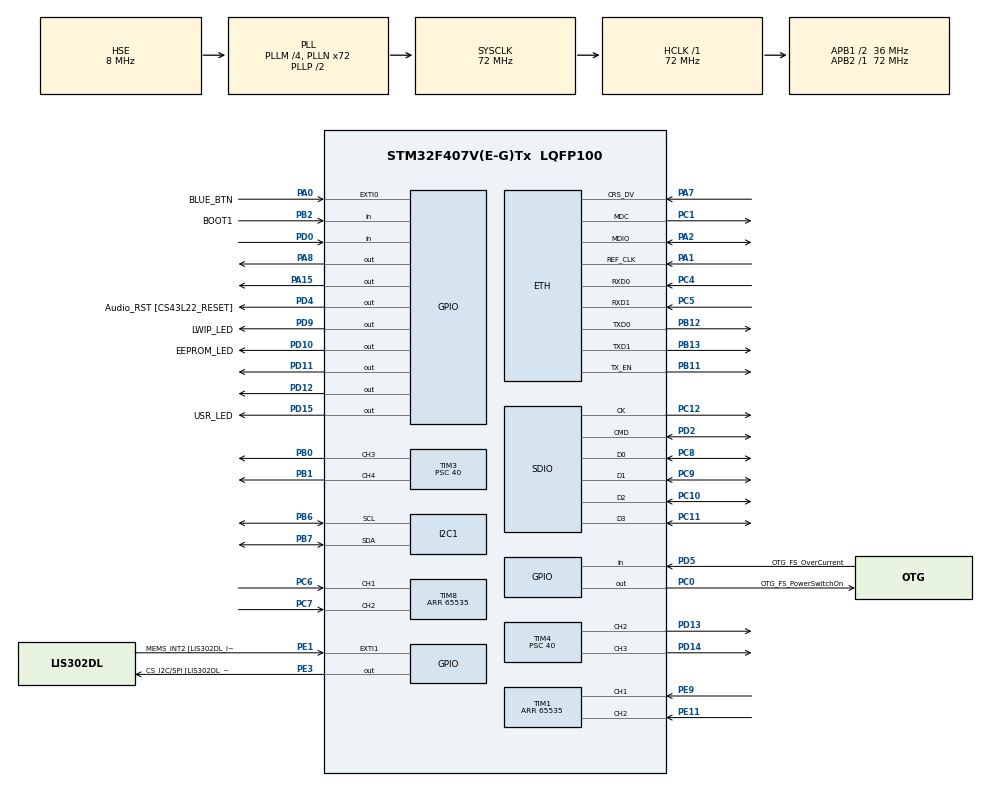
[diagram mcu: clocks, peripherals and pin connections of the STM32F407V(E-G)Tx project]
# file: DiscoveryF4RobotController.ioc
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ETH.MediaInterface=ETH_MEDIA_INTERFACE_RMII
ETH.PhyAddress=0
FATFS.BSP.number=1
FATFS0.BSP.STBoard=false
FATFS0.BSP.api=Unknown
FATFS0.BSP.i2caddr=0
FATFS0.BSP.instance=PD0
FATFS0.BSP.ip=GPIO
FATFS0.BSP.mode=Input
FATFS0.BSP.name=Detect_SDIO
FATFS0.BSP.solution=PD0
FREERTOS.HEAP_NUMBER=5
FREERTOS.Tasks01=defaultTask,0,128,StartDefaultTask,Default,NULL
LWIP.ARP_MAXAGE=6000
LWIP.CHECKSUM_CHECK_IP=1
LWIP.CHECKSUM_GEN_IP=1
LWIP.GATEWAY_ADDRESS=198.168.002.001
LWIP.IP_ADDRESS=192.168.002.114
LWIP.LWIP_ARP=1
LWIP.LWIP_DHCP=0
LWIP.MEMP_NUM_TCP_SEG=24
LWIP.MEM_SIZE=2048
LWIP.NETMASK_ADDRESS=255.255.255.000
LWIP.TCP_MSS=460
LWIP.TCP_SND_BUF=1840
LWIP.TCP_WND=2048
LWIP.Version=v2.0.3_Cube
Mcu.Family=STM32F4
Mcu.Name=STM32F407V(E-G)Tx
Mcu.Package=LQFP100
NVIC.ETH_IRQn=true\:5\:0\:false\:false\:true\:true\:false\:true
NVIC.EXTI0_IRQn=true\:5\:0\:false\:false\:true\:true\:true\:true
NVIC.PriorityGroup=NVIC_PRIORITYGROUP_4
NVIC.TIM2_IRQn=true\:0\:0\:false\:false\:true\:false\:false\:true
NVIC.TimeBase=TIM2_IRQn
NVIC.TimeBaseIP=TIM2
PA0-WKUP.GPIO_Label=BLUE_BTN
PA0-WKUP.GPIO_PuPd=GPIO_PULLDOWN
PA0-WKUP.Signal=GPXTI0
PA1.Mode=RMII
PA1.Signal=ETH_REF_CLK
PA13.GPIO_Label=SWDIO
PA13.Mode=Serial_Wire
PA13.Signal=SYS_JTMS-SWDIO
PA14.GPIO_Label=SWCLK
PA14.Mode=Serial_Wire
PA14.Signal=SYS_JTCK-SWCLK
PA15.Signal=GPIO_Output
PA2.Mode=RMII
PA2.Signal=ETH_MDIO
PA7.Mode=RMII
PA7.Signal=ETH_CRS_DV
PA8.Signal=GPIO_Output
PB0.Signal=S_TIM3_CH3
PB1.Signal=S_TIM3_CH4
PB11.Mode=RMII
PB11.Signal=ETH_TX_EN
PB12.Mode=RMII
PB12.Signal=ETH_TXD0
PB13.Mode=RMII
PB13.Signal=ETH_TXD1
PB2.GPIO_Label=BOOT1
PB2.GPIO_Mode=GPIO_MODE_INPUT
PB2.GPIO_PuPd=GPIO_NOPULL
PB2.Signal=GPIO_Input
PB6.Mode=I2C
PB6.Signal=I2C1_SCL
PB7.Mode=I2C
PB7.Signal=I2C1_SDA
PC0.GPIO_Label=OTG_FS_PowerSwitchOn
PC0.GPIO_PuPd=GPIO_NOPULL
PC0.GPIO_Speed=GPIO_SPEED_FREQ_LOW
PC0.PinState=GPIO_PIN_SET
PC0.Signal=GPIO_Output
PC1.Mode=RMII
PC1.Signal=ETH_MDC
PC10.Mode=SD_4_bits_Wide_bus
PC10.Signal=SDIO_D2
PC11.Mode=SD_4_bits_Wide_bus
PC11.Signal=SDIO_D3
PC12.Mode=SD_4_bits_Wide_bus
PC12.Signal=SDIO_CK
PC4.Mode=RMII
PC4.Signal=ETH_RXD0
PC5.Mode=RMII
PC5.Signal=ETH_RXD1
PC6.Signal=S_TIM8_CH1
PC7.Signal=S_TIM8_CH2
PC8.Mode=SD_4_bits_Wide_bus
PC8.Signal=SDIO_D0
PC9.Mode=SD_4_bits_Wide_bus
PC9.Signal=SDIO_D1
PD0.Signal=GPIO_Input
PD10.GPIO_Label=EEPROM_LED
PD10.Signal=GPIO_Output
PD11.Signal=GPIO_Output
PD12.Signal=GPIO_Output
PD13.Signal=S_TIM4_CH2
PD14.Signal=S_TIM4_CH3
PD15.GPIO_Label=USR_LED
PD15.Signal=GPIO_Output
PD2.Mode=SD_4_bits_Wide_bus
PD2.Signal=SDIO_CMD
PD4.GPIO_Label=Audio_RST [CS43L22_RESET]
PD4.GPIO_PuPd=GPIO_NOPULL
PD4.GPIO_Speed=GPIO_SPEED_FREQ_LOW
PD4.Signal=GPIO_Output
PD5.GPIO_Label=OTG_FS_OverCurrent
PD5.GPIO_Mode=GPIO_MODE_INPUT
PD5.GPIO_PuPd=GPIO_NOPULL
PD5.Signal=GPIO_Input
PD9.GPIO_Label=LWIP_LED
PD9.Signal=GPIO_Output
PE1.GPIO_Label=MEMS_INT2 [LIS302DL_INT2]
PE1.GPIO_ModeDefaultEXTI=GPIO_MODE_EVT_RISING
PE1.GPIO_PuPd=GPIO_NOPULL
PE1.Signal=GPXTI1
PE11.Signal=S_TIM1_CH2
PE3.GPIO_Label=CS_I2C/SPI [LIS302DL_CS_I2C/SPI]
PE3.GPIO_PuPd=GPIO_NOPULL
PE3.GPIO_Speed=GPIO_SPEED_FREQ_LOW
PE3.Signal=GPIO_Output
PE9.Signal=S_TIM1_CH1
PH0-OSC_IN.GPIO_Label=PH0-OSC_IN
PH0-OSC_IN.Mode=HSE-External-Clock-Source
PH0-OSC_IN.Signal=RCC_OSC_IN
PH1-OSC_OUT.GPIO_Label=PH1-OSC_OUT
PH1-OSC_OUT.Mode=HSE-External-Clock-Source
PH1-OSC_OUT.Signal=RCC_OSC_OUT
ProjectManager.HeapSize=0x200
ProjectManager.StackSize=0x400
ProjectManager.TargetToolchain=STM32CubeIDE
RCC.48MHZClocksFreq_Value=20571428.57142857
RCC.AHBFreq_Value=72000000
RCC.APB1CLKDivider=RCC_HCLK_DIV2
RCC.APB1Freq_Value=36000000
RCC.APB1TimFreq_Value=72000000
RCC.APB2Freq_Value=72000000
RCC.APB2TimFreq_Value=72000000
RCC.CortexFreq_Value=72000000
RCC.HCLKFreq_Value=72000000
RCC.HSE_VALUE=8000000
RCC.HSI_VALUE=16000000
RCC.LSE_VALUE=32768
RCC.PLLM=4
RCC.PLLN=72
RCC.PLLQ=7
RCC.PLLSourceVirtual=RCC_PLLSOURCE_HSE
RCC.SYSCLKFreq_VALUE=72000000
RCC.SYSCLKSource=RCC_SYSCLKSOURCE_PLLCLK
RCC.VCOOutputFreq_Value=144000000
SH.S_TIM1_CH1.0=TIM1_CH1,Encoder_Interface
SH.S_TIM1_CH2.0=TIM1_CH2,Encoder_Interface
SH.S_TIM3_CH3.0=TIM3_CH3,PWM Generation3 CH3
SH.S_TIM3_CH4.0=TIM3_CH4,PWM Generation4 CH4
SH.S_TIM4_CH2.0=TIM4_CH2,PWM Generation2 CH2
SH.S_TIM4_CH3.0=TIM4_CH3,PWM Generation3 CH3
SH.S_TIM8_CH1.0=TIM8_CH1,Encoder_Interface
SH.S_TIM8_CH2.0=TIM8_CH2,Encoder_Interface
TIM1.EncoderMode=TIM_ENCODERMODE_TI12
TIM1.IC1Filter=0
TIM1.IC1Prescaler=TIM_ICPSC_DIV1
TIM1.IC2Filter=0
TIM1.IC2Polarity=TIM_ICPOLARITY_FALLING
TIM1.IC2Prescaler=TIM_ICPSC_DIV1
TIM1.Period=65535
TIM3.Channel-PWM\ Generation3\ CH3=TIM_CHANNEL_3
TIM3.Channel-PWM\ Generation4\ CH4=TIM_CHANNEL_4
TIM3.Period=256
TIM3.Prescaler=40
TIM4.Channel-PWM\ Generation2\ CH2=TIM_CHANNEL_2
TIM4.Channel-PWM\ Generation3\ CH3=TIM_CHANNEL_3
TIM4.Period=256
TIM4.Prescaler=40
TIM8.EncoderMode=TIM_ENCODERMODE_TI12
TIM8.IC1Filter=0
TIM8.IC1Prescaler=TIM_ICPSC_DIV1
TIM8.IC2Filter=15
TIM8.IC2Polarity=TIM_ICPOLARITY_FALLING
TIM8.IC2Prescaler=TIM_ICPSC_DIV1
TIM8.Period=65535
VP_FATFS_VS_SDIO.Mode=SDIO
VP_FREERTOS_VS_CMSIS_V1.Mode=CMSIS_V1
VP_LWIP_VS_Enabled.Mode=Enabled
VP_RTC_VS_RTC_Activate.Mode=RTC_Enabled
VP_SYS_VS_tim2.Mode=TIM2
VP_TIM3_VS_ClockSourceINT.Mode=Internal
VP_TIM4_VS_ClockSourceINT.Mode=Internal
board=STM32F407G-DISC1

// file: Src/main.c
/* USER CODE BEGIN Header */
/**
  ******************************************************************************
  * @file           : main.c
  * @brief          : Main program body
  ******************************************************************************
  * @attention
  *
  * <h2><center>&copy; Copyright (c) 2019 STMicroelectronics.
  * All rights reserved.</center></h2>
  *
  * This software component is licensed by ST under BSD 3-Clause license,
  * the "License"; You may not use this file except in compliance with the
  * License. You may obtain a copy of the License at:
  *                        opensource.org/licenses/BSD-3-Clause
  *
  ******************************************************************************
  */
/* USER CODE END Header */

#include "main.h"
#include "cmsis_os.h"
#include "fatfs.h"
#include "lwip.h"

/* USER CODE BEGIN Includes */
#include "mainpp.h"
/* USER CODE END Includes */

I2C_HandleTypeDef hi2c1;

RTC_HandleTypeDef hrtc;

SD_HandleTypeDef hsd;

TIM_HandleTypeDef htim1;
TIM_HandleTypeDef htim3;
TIM_HandleTypeDef htim4;
TIM_HandleTypeDef htim8;

osThreadId defaultTaskHandle;

void SystemClock_Config(void);
static void MX_GPIO_Init(void);
static void MX_RTC_Init(void);
static void MX_TIM1_Init(void);
static void MX_TIM8_Init(void);
static void MX_TIM3_Init(void);
static void MX_TIM4_Init(void);
static void MX_I2C1_Init(void);
static void MX_SDIO_SD_Init(void);
void StartDefaultTask(void const * argument);

int main(void)
{
  /* USER CODE BEGIN 1 */
	memory_setup();
  /* USER CODE END 1 */

  /* MCU Configuration--------------------------------------------------------*/

  /* Reset of all peripherals, Initializes the Flash interface and the Systick. */
  HAL_Init();

  /* Configure the system clock */
  SystemClock_Config();

  /* Initialize all configured peripherals */
  MX_GPIO_Init();
  MX_RTC_Init();
  MX_TIM1_Init();
  MX_TIM8_Init();
  MX_TIM3_Init();
  MX_TIM4_Init();
  MX_I2C1_Init();
  MX_SDIO_SD_Init();

  /* Create the thread(s) */
  /* definition and creation of defaultTask */
  osThreadDef(defaultTask, StartDefaultTask, osPriorityNormal, 0, 128);
  defaultTaskHandle = osThreadCreate(osThread(defaultTask), NULL);

  /* Start scheduler */
  osKernelStart();

  /* We should never get here as control is now taken by the scheduler */

  /* Infinite loop */
  while (1)
  {

  }
}

void SystemClock_Config(void)
{
  RCC_OscInitTypeDef RCC_OscInitStruct = {0};
  RCC_ClkInitTypeDef RCC_ClkInitStruct = {0};
  RCC_PeriphCLKInitTypeDef PeriphClkInitStruct = {0};

  /** Configure the main internal regulator output voltage
  */
  __HAL_RCC_PWR_CLK_ENABLE();
  __HAL_PWR_VOLTAGESCALING_CONFIG(PWR_REGULATOR_VOLTAGE_SCALE1);
  /** Initializes the CPU, AHB and APB busses clocks
  */
  RCC_OscInitStruct.OscillatorType = RCC_OSCILLATORTYPE_LSI|RCC_OSCILLATORTYPE_HSE;
  RCC_OscInitStruct.HSEState = RCC_HSE_BYPASS;
  RCC_OscInitStruct.LSIState = RCC_LSI_ON;
  RCC_OscInitStruct.PLL.PLLState = RCC_PLL_ON;
  RCC_OscInitStruct.PLL.PLLSource = RCC_PLLSOURCE_HSE;
  RCC_OscInitStruct.PLL.PLLM = 4;
  RCC_OscInitStruct.PLL.PLLN = 72;
  RCC_OscInitStruct.PLL.PLLP = RCC_PLLP_DIV2;
  RCC_OscInitStruct.PLL.PLLQ = 7;
  if (HAL_RCC_OscConfig(&RCC_OscInitStruct) != HAL_OK)
  {
    Error_Handler();
  }
  /** Initializes the CPU, AHB and APB busses clocks
  */
  RCC_ClkInitStruct.ClockType = RCC_CLOCKTYPE_HCLK|RCC_CLOCKTYPE_SYSCLK
                              |RCC_CLOCKTYPE_PCLK1|RCC_CLOCKTYPE_PCLK2;
  RCC_ClkInitStruct.SYSCLKSource = RCC_SYSCLKSOURCE_PLLCLK;
  RCC_ClkInitStruct.AHBCLKDivider = RCC_SYSCLK_DIV1;
  RCC_ClkInitStruct.APB1CLKDivider = RCC_HCLK_DIV2;
  RCC_ClkInitStruct.APB2CLKDivider = RCC_HCLK_DIV1;

  if (HAL_RCC_ClockConfig(&RCC_ClkInitStruct, FLASH_LATENCY_2) != HAL_OK)
  {
    Error_Handler();
  }
  PeriphClkInitStruct.PeriphClockSelection = RCC_PERIPHCLK_RTC;
  PeriphClkInitStruct.RTCClockSelection = RCC_RTCCLKSOURCE_LSI;
  if (HAL_RCCEx_PeriphCLKConfig(&PeriphClkInitStruct) != HAL_OK)
  {
    Error_Handler();
  }
}

static void MX_I2C1_Init(void)
{

  hi2c1.Instance = I2C1;
  hi2c1.Init.ClockSpeed = 100000;
  hi2c1.Init.DutyCycle = I2C_DUTYCYCLE_2;
  hi2c1.Init.OwnAddress1 = 0;
  hi2c1.Init.AddressingMode = I2C_ADDRESSINGMODE_7BIT;
  hi2c1.Init.DualAddressMode = I2C_DUALADDRESS_DISABLE;
  hi2c1.Init.OwnAddress2 = 0;
  hi2c1.Init.GeneralCallMode = I2C_GENERALCALL_DISABLE;
  hi2c1.Init.NoStretchMode = I2C_NOSTRETCH_DISABLE;
  if (HAL_I2C_Init(&hi2c1) != HAL_OK)
  {
    Error_Handler();
  }

}

static void MX_RTC_Init(void)
{

  /** Initialize RTC Only
  */
  hrtc.Instance = RTC;
  hrtc.Init.HourFormat = RTC_HOURFORMAT_24;
  hrtc.Init.AsynchPrediv = 127;
  hrtc.Init.SynchPrediv = 255;
  hrtc.Init.OutPut = RTC_OUTPUT_DISABLE;
  hrtc.Init.OutPutPolarity = RTC_OUTPUT_POLARITY_HIGH;
  hrtc.Init.OutPutType = RTC_OUTPUT_TYPE_OPENDRAIN;
  if (HAL_RTC_Init(&hrtc) != HAL_OK)
  {
    Error_Handler();
  }

}

static void MX_SDIO_SD_Init(void)
{

  hsd.Instance = SDIO;
  hsd.Init.ClockEdge = SDIO_CLOCK_EDGE_RISING;
  hsd.Init.ClockBypass = SDIO_CLOCK_BYPASS_DISABLE;
  hsd.Init.ClockPowerSave = SDIO_CLOCK_POWER_SAVE_DISABLE;
  hsd.Init.BusWide = SDIO_BUS_WIDE_1B;
  hsd.Init.HardwareFlowControl = SDIO_HARDWARE_FLOW_CONTROL_DISABLE;
  hsd.Init.ClockDiv = 0;

}

static void MX_TIM1_Init(void)
{

  TIM_Encoder_InitTypeDef sConfig = {0};
  TIM_MasterConfigTypeDef sMasterConfig = {0};

  htim1.Instance = TIM1;
  htim1.Init.Prescaler = 0;
  htim1.Init.CounterMode = TIM_COUNTERMODE_UP;
  htim1.Init.Period = 65535;
  htim1.Init.ClockDivision = TIM_CLOCKDIVISION_DIV1;
  htim1.Init.RepetitionCounter = 0;
  htim1.Init.AutoReloadPreload = TIM_AUTORELOAD_PRELOAD_DISABLE;
  sConfig.EncoderMode = TIM_ENCODERMODE_TI12;
  sConfig.IC1Polarity = TIM_ICPOLARITY_RISING;
  sConfig.IC1Selection = TIM_ICSELECTION_DIRECTTI;
  sConfig.IC1Prescaler = TIM_ICPSC_DIV1;
  sConfig.IC1Filter = 0;
  sConfig.IC2Polarity = TIM_ICPOLARITY_FALLING;
  sConfig.IC2Selection = TIM_ICSELECTION_DIRECTTI;
  sConfig.IC2Prescaler = TIM_ICPSC_DIV1;
  sConfig.IC2Filter = 0;
  if (HAL_TIM_Encoder_Init(&htim1, &sConfig) != HAL_OK)
  {
    Error_Handler();
  }
  sMasterConfig.MasterOutputTrigger = TIM_TRGO_RESET;
  sMasterConfig.MasterSlaveMode = TIM_MASTERSLAVEMODE_DISABLE;
  if (HAL_TIMEx_MasterConfigSynchronization(&htim1, &sMasterConfig) != HAL_OK)
  {
    Error_Handler();
  }

}

static void MX_TIM3_Init(void)
{

  TIM_ClockConfigTypeDef sClockSourceConfig = {0};
  TIM_MasterConfigTypeDef sMasterConfig = {0};
  TIM_OC_InitTypeDef sConfigOC = {0};

  htim3.Instance = TIM3;
  htim3.Init.Prescaler = 40;
  htim3.Init.CounterMode = TIM_COUNTERMODE_UP;
  htim3.Init.Period = 256;
  htim3.Init.ClockDivision = TIM_CLOCKDIVISION_DIV1;
  htim3.Init.AutoReloadPreload = TIM_AUTORELOAD_PRELOAD_DISABLE;
  if (HAL_TIM_Base_Init(&htim3) != HAL_OK)
  {
    Error_Handler();
  }
  sClockSourceConfig.ClockSource = TIM_CLOCKSOURCE_INTERNAL;
  if (HAL_TIM_ConfigClockSource(&htim3, &sClockSourceConfig) != HAL_OK)
  {
    Error_Handler();
  }
  if (HAL_TIM_PWM_Init(&htim3) != HAL_OK)
  {
    Error_Handler();
  }
  sMasterConfig.MasterOutputTrigger = TIM_TRGO_RESET;
  sMasterConfig.MasterSlaveMode = TIM_MASTERSLAVEMODE_DISABLE;
  if (HAL_TIMEx_MasterConfigSynchronization(&htim3, &sMasterConfig) != HAL_OK)
  {
    Error_Handler();
  }
  sConfigOC.OCMode = TIM_OCMODE_PWM1;
  sConfigOC.Pulse = 0;
  sConfigOC.OCPolarity = TIM_OCPOLARITY_HIGH;
  sConfigOC.OCFastMode = TIM_OCFAST_DISABLE;
  if (HAL_TIM_PWM_ConfigChannel(&htim3, &sConfigOC, TIM_CHANNEL_3) != HAL_OK)
  {
    Error_Handler();
  }
  if (HAL_TIM_PWM_ConfigChannel(&htim3, &sConfigOC, TIM_CHANNEL_4) != HAL_OK)
  {
    Error_Handler();
  }
  HAL_TIM_MspPostInit(&htim3);

}

static void MX_TIM4_Init(void)
{

  TIM_ClockConfigTypeDef sClockSourceConfig = {0};
  TIM_MasterConfigTypeDef sMasterConfig = {0};
  TIM_OC_InitTypeDef sConfigOC = {0};

  htim4.Instance = TIM4;
  htim4.Init.Prescaler = 40;
  htim4.Init.CounterMode = TIM_COUNTERMODE_UP;
  htim4.Init.Period = 256;
  htim4.Init.ClockDivision = TIM_CLOCKDIVISION_DIV1;
  htim4.Init.AutoReloadPreload = TIM_AUTORELOAD_PRELOAD_DISABLE;
  if (HAL_TIM_Base_Init(&htim4) != HAL_OK)
  {
    Error_Handler();
  }
  sClockSourceConfig.ClockSource = TIM_CLOCKSOURCE_INTERNAL;
  if (HAL_TIM_ConfigClockSource(&htim4, &sClockSourceConfig) != HAL_OK)
  {
    Error_Handler();
  }
  if (HAL_TIM_PWM_Init(&htim4) != HAL_OK)
  {
    Error_Handler();
  }
  sMasterConfig.MasterOutputTrigger = TIM_TRGO_RESET;
  sMasterConfig.MasterSlaveMode = TIM_MASTERSLAVEMODE_DISABLE;
  if (HAL_TIMEx_MasterConfigSynchronization(&htim4, &sMasterConfig) != HAL_OK)
  {
    Error_Handler();
  }
  sConfigOC.OCMode = TIM_OCMODE_PWM1;
  sConfigOC.Pulse = 0;
  sConfigOC.OCPolarity = TIM_OCPOLARITY_HIGH;
  sConfigOC.OCFastMode = TIM_OCFAST_DISABLE;
  if (HAL_TIM_PWM_ConfigChannel(&htim4, &sConfigOC, TIM_CHANNEL_2) != HAL_OK)
  {
    Error_Handler();
  }
  if (HAL_TIM_PWM_ConfigChannel(&htim4, &sConfigOC, TIM_CHANNEL_3) != HAL_OK)
  {
    Error_Handler();
  }
  HAL_TIM_MspPostInit(&htim4);

}

static void MX_TIM8_Init(void)
{

  TIM_Encoder_InitTypeDef sConfig = {0};
  TIM_MasterConfigTypeDef sMasterConfig = {0};

  htim8.Instance = TIM8;
  htim8.Init.Prescaler = 0;
  htim8.Init.CounterMode = TIM_COUNTERMODE_UP;
  htim8.Init.Period = 65535;
  htim8.Init.ClockDivision = TIM_CLOCKDIVISION_DIV1;
  htim8.Init.RepetitionCounter = 0;
  htim8.Init.AutoReloadPreload = TIM_AUTORELOAD_PRELOAD_DISABLE;
  sConfig.EncoderMode = TIM_ENCODERMODE_TI12;
  sConfig.IC1Polarity = TIM_ICPOLARITY_RISING;
  sConfig.IC1Selection = TIM_ICSELECTION_DIRECTTI;
  sConfig.IC1Prescaler = TIM_ICPSC_DIV1;
  sConfig.IC1Filter = 0;
  sConfig.IC2Polarity = TIM_ICPOLARITY_FALLING;
  sConfig.IC2Selection = TIM_ICSELECTION_DIRECTTI;
  sConfig.IC2Prescaler = TIM_ICPSC_DIV1;
  sConfig.IC2Filter = 15;
  if (HAL_TIM_Encoder_Init(&htim8, &sConfig) != HAL_OK)
  {
    Error_Handler();
  }
  sMasterConfig.MasterOutputTrigger = TIM_TRGO_RESET;
  sMasterConfig.MasterSlaveMode = TIM_MASTERSLAVEMODE_DISABLE;
  if (HAL_TIMEx_MasterConfigSynchronization(&htim8, &sMasterConfig) != HAL_OK)
  {
    Error_Handler();
  }

}

static void MX_GPIO_Init(void)
{
  GPIO_InitTypeDef GPIO_InitStruct = {0};

  /* GPIO Ports Clock Enable */
  __HAL_RCC_GPIOE_CLK_ENABLE();
  __HAL_RCC_GPIOH_CLK_ENABLE();
  __HAL_RCC_GPIOC_CLK_ENABLE();
  __HAL_RCC_GPIOA_CLK_ENABLE();
  __HAL_RCC_GPIOB_CLK_ENABLE();
  __HAL_RCC_GPIOD_CLK_ENABLE();

  /*Configure GPIO pin Output Level */
  HAL_GPIO_WritePin(CS_I2C_SPI_GPIO_Port, CS_I2C_SPI_Pin, GPIO_PIN_RESET);

  /*Configure GPIO pin Output Level */
  HAL_GPIO_WritePin(OTG_FS_PowerSwitchOn_GPIO_Port, OTG_FS_PowerSwitchOn_Pin, GPIO_PIN_SET);

  /*Configure GPIO pin Output Level */
  HAL_GPIO_WritePin(GPIOD, LWIP_LED_Pin|EEPROM_LED_Pin|GPIO_PIN_11|GPIO_PIN_12
                          |USR_LED_Pin|Audio_RST_Pin, GPIO_PIN_RESET);

  /*Configure GPIO pin Output Level */
  HAL_GPIO_WritePin(GPIOA, GPIO_PIN_8|GPIO_PIN_15, GPIO_PIN_RESET);

  /*Configure GPIO pin : CS_I2C_SPI_Pin */
  GPIO_InitStruct.Pin = CS_I2C_SPI_Pin;
  GPIO_InitStruct.Mode = GPIO_MODE_OUTPUT_PP;
  GPIO_InitStruct.Pull = GPIO_NOPULL;
  GPIO_InitStruct.Speed = GPIO_SPEED_FREQ_LOW;
  HAL_GPIO_Init(CS_I2C_SPI_GPIO_Port, &GPIO_InitStruct);

  /*Configure GPIO pin : OTG_FS_PowerSwitchOn_Pin */
  GPIO_InitStruct.Pin = OTG_FS_PowerSwitchOn_Pin;
  GPIO_InitStruct.Mode = GPIO_MODE_OUTPUT_PP;
  GPIO_InitStruct.Pull = GPIO_NOPULL;
  GPIO_InitStruct.Speed = GPIO_SPEED_FREQ_LOW;
  HAL_GPIO_Init(OTG_FS_PowerSwitchOn_GPIO_Port, &GPIO_InitStruct);

  /*Configure GPIO pin : BLUE_BTN_Pin */
  GPIO_InitStruct.Pin = BLUE_BTN_Pin;
  GPIO_InitStruct.Mode = GPIO_MODE_IT_RISING;
  GPIO_InitStruct.Pull = GPIO_PULLDOWN;
  HAL_GPIO_Init(BLUE_BTN_GPIO_Port, &GPIO_InitStruct);

  /*Configure GPIO pin : BOOT1_Pin */
  GPIO_InitStruct.Pin = BOOT1_Pin;
  GPIO_InitStruct.Mode = GPIO_MODE_INPUT;
  GPIO_InitStruct.Pull = GPIO_NOPULL;
  HAL_GPIO_Init(BOOT1_GPIO_Port, &GPIO_InitStruct);

  /*Configure GPIO pins : LWIP_LED_Pin EEPROM_LED_Pin PD11 PD12
                           USR_LED_Pin Audio_RST_Pin */
  GPIO_InitStruct.Pin = LWIP_LED_Pin|EEPROM_LED_Pin|GPIO_PIN_11|GPIO_PIN_12
                          |USR_LED_Pin|Audio_RST_Pin;
  GPIO_InitStruct.Mode = GPIO_MODE_OUTPUT_PP;
  GPIO_InitStruct.Pull = GPIO_NOPULL;
  GPIO_InitStruct.Speed = GPIO_SPEED_FREQ_LOW;
  HAL_GPIO_Init(GPIOD, &GPIO_InitStruct);

  /*Configure GPIO pins : PA8 PA15 */
  GPIO_InitStruct.Pin = GPIO_PIN_8|GPIO_PIN_15;
  GPIO_InitStruct.Mode = GPIO_MODE_OUTPUT_PP;
  GPIO_InitStruct.Pull = GPIO_NOPULL;
  GPIO_InitStruct.Speed = GPIO_SPEED_FREQ_LOW;
  HAL_GPIO_Init(GPIOA, &GPIO_InitStruct);

  /*Configure GPIO pins : PD0 OTG_FS_OverCurrent_Pin */
  GPIO_InitStruct.Pin = GPIO_PIN_0|OTG_FS_OverCurrent_Pin;
  GPIO_InitStruct.Mode = GPIO_MODE_INPUT;
  GPIO_InitStruct.Pull = GPIO_NOPULL;
  HAL_GPIO_Init(GPIOD, &GPIO_InitStruct);

  /*Configure GPIO pin : MEMS_INT2_Pin */
  GPIO_InitStruct.Pin = MEMS_INT2_Pin;
  GPIO_InitStruct.Mode = GPIO_MODE_EVT_RISING;
  GPIO_InitStruct.Pull = GPIO_NOPULL;
  HAL_GPIO_Init(MEMS_INT2_GPIO_Port, &GPIO_InitStruct);

  /* EXTI interrupt init*/
  HAL_NVIC_SetPriority(EXTI0_IRQn, 5, 0);
  HAL_NVIC_EnableIRQ(EXTI0_IRQn);

}

/* USER CODE BEGIN 4 */
//---------------------------------------------------------------

void HAL_GPIO_EXTI_Callback(uint16_t GPIO_Pin)

{

 if(GPIO_Pin == BLUE_BTN_Pin) {
	 	 set_default();
 } else{

   __NOP();

 }

}

/* USER CODE END 4 */

void StartDefaultTask(void const * argument)
{

  /* init code for LWIP */

  /* init code for FATFS */
  MX_FATFS_Init();

  /* USER CODE BEGIN 5 */
  external_memory_init(&hi2c1);
  osDelay(100);
  LWIP_Init(get_local_ip_ptr(), get_network_mask_ptr(), get_gateaway_ptr());
  threds_setup(&htim3, &htim4, &htim8, &htim1) ;

  for(;;)
  {
    osDelay(100);
  }
  /* USER CODE END 5 */
}

void HAL_TIM_PeriodElapsedCallback(TIM_HandleTypeDef *htim)
{
  if (htim->Instance == TIM2) {
    HAL_IncTick();
  }
}

void Error_Handler(void)
{
}

/************************ (C) COPYRIGHT STMicroelectronics *****END OF FILE****/
